# iostm32f205zx register map
Registers are 32-bit, access not given, no defined reset value unless marked. A register's access mark holds for its fields unless they carry their own. Addresses are absolute; registers are grouped by the start of their names; [hi:lo] are bit positions; {n}, {i} and the like mark numbered series.

## DBGMCU
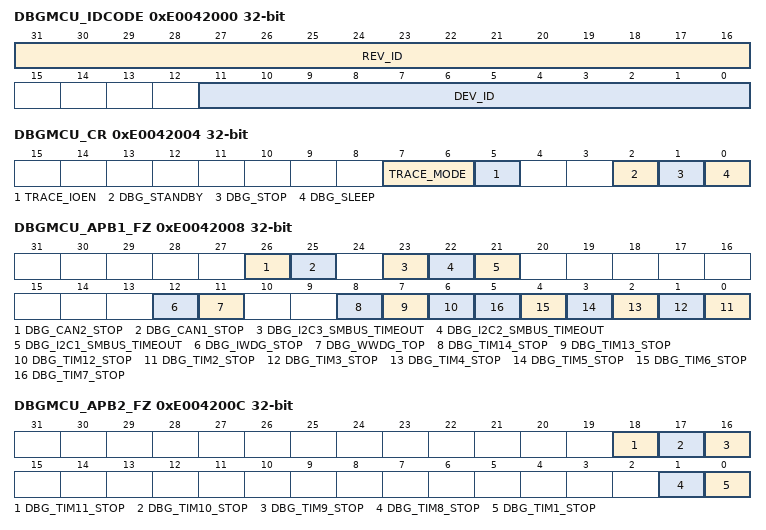
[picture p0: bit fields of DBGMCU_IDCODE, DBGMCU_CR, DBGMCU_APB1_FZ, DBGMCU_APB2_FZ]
0xE0042000 DBGMCU_IDCODE
  [31:16] REV_ID, [11:0] DEV_ID
0xE0042004 DBGMCU_CR
  [7:6] TRACE_MODE, [5] TRACE_IOEN, [2] DBG_STANDBY, [1] DBG_STOP, [0] DBG_SLEEP
0xE0042008 DBGMCU_APB1_FZ
  [26] DBG_CAN2_STOP, [25] DBG_CAN1_STOP, [23] DBG_I2C3_SMBUS_TIMEOUT, [22] DBG_I2C2_SMBUS_TIMEOUT, [21] DBG_I2C1_SMBUS_TIMEOUT, [12] DBG_IWDG_STOP, [11] DBG_WWDG_TOP, [8] DBG_TIM14_STOP, [7] DBG_TIM13_STOP, [6] DBG_TIM12_STOP, [n-2] DBG_TIM{n}_STOP (n=2..7)
0xE004200C DBGMCU_APB2_FZ
  [18] DBG_TIM11_STOP, [17] DBG_TIM10_STOP, [16] DBG_TIM9_STOP, [1] DBG_TIM8_STOP, [0] DBG_TIM1_STOP

## PWR
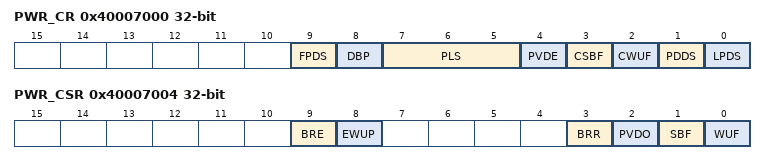
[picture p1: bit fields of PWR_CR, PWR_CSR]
0x40007000 PWR_CR
  [9] FPDS, [8] DBP, [7:5] PLS, [4] PVDE, [3] CSBF, [2] CWUF, [1] PDDS, [0] LPDS
0x40007004 PWR_CSR
  [9] BRE, [8] EWUP, [3] BRR, [2] PVDO, [1] SBF, [0] WUF

## RCC
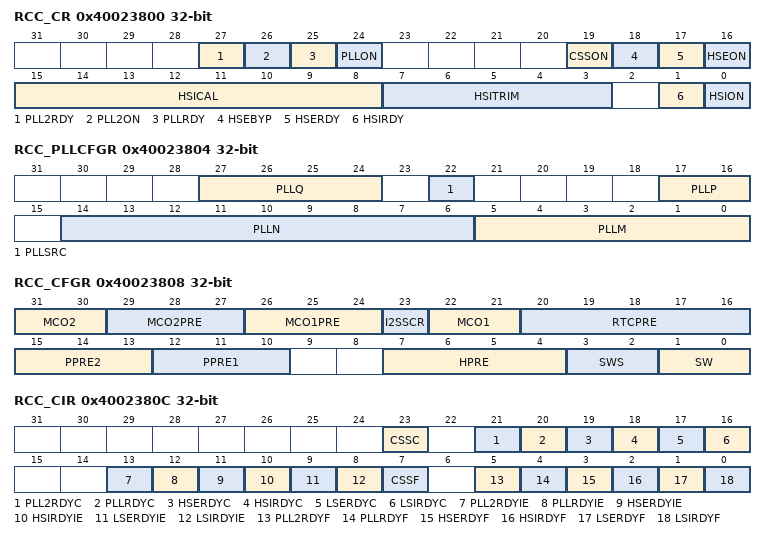
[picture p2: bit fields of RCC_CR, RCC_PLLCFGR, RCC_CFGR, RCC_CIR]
0x40023800 RCC_CR
  [27] PLL2RDY, [26] PLL2ON, [25] PLLRDY, [24] PLLON, [19] CSSON, [18] HSEBYP, [17] HSERDY, [16] HSEON, [15:8] HSICAL, [7:3] HSITRIM, [1] HSIRDY, [0] HSION
0x40023804 RCC_PLLCFGR
  [27:24] PLLQ, [22] PLLSRC, [17:16] PLLP, [14:6] PLLN, [5:0] PLLM
0x40023808 RCC_CFGR
  [31:30] MCO2, [29:27] MCO2PRE, [26:24] MCO1PRE, [23] I2SSCR, [22:21] MCO1, [20:16] RTCPRE, [15:13] PPRE2, [12:10] PPRE1, [7:4] HPRE, [3:2] SWS, [1:0] SW
0x4002380C RCC_CIR
  [23] CSSC, [21] PLL2RDYC, [20] PLLRDYC, [19] HSERDYC, [18] HSIRDYC, [17] LSERDYC, [16] LSIRDYC, [13] PLL2RDYIE, [12] PLLRDYIE, [11] HSERDYIE, [10] HSIRDYIE, [9] LSERDYIE, [8] LSIRDYIE, [7] CSSF, [5] PLL2RDYF, [4] PLLRDYF, [3] HSERDYF, [2] HSIRDYF, [1] LSERDYF, [0] LSIRDYF
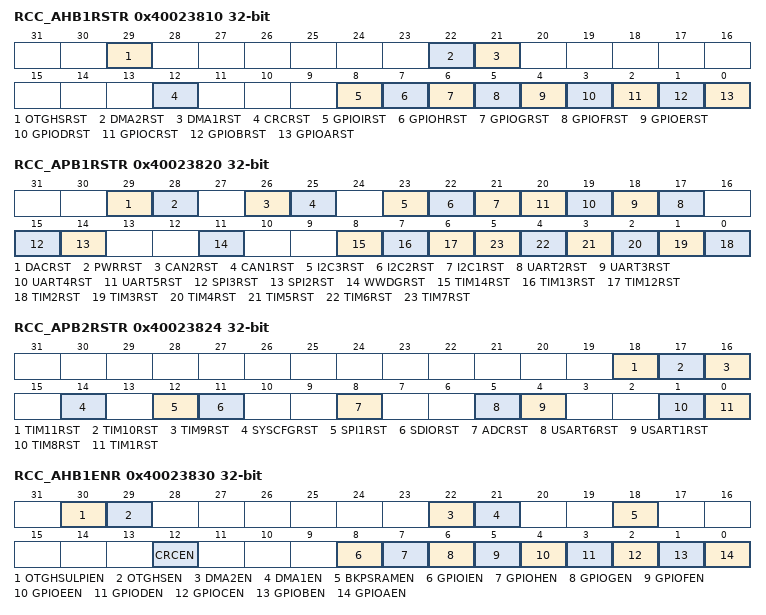
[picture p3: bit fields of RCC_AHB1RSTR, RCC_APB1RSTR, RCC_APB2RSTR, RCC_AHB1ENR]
0x40023810 RCC_AHB1RSTR
  [29] OTGHSRST, [22] DMA2RST, [21] DMA1RST, [12] CRCRST, [8] GPIOIRST, [7] GPIOHRST, [6] GPIOGRST, [5] GPIOFRST, [4] GPIOERST, [3] GPIODRST, [2] GPIOCRST, [1] GPIOBRST, [0] GPIOARST
0x40023814 RCC_AHB2RSTR
  [6] RNGRST
0x40023818 RCC_AHB3RSTR
  [0] FSMCRST
0x40023820 RCC_APB1RSTR
  [29] DACRST, [28] PWRRST, [26] CAN2RST, [25] CAN1RST, [23] I2C3RST, [22] I2C2RST, [21] I2C1RST, [n+15] UART{n}RST (n=2..5), [15] SPI3RST, [14] SPI2RST, [11] WWDGRST, [8] TIM14RST, [7] TIM13RST, [6] TIM12RST, [n-2] TIM{n}RST (n=2..7)
0x40023824 RCC_APB2RSTR
  [18] TIM11RST, [17] TIM10RST, [16] TIM9RST, [14] SYSCFGRST, [12] SPI1RST, [11] SDIORST, [8] ADCRST, [5] USART6RST, [4] USART1RST, [1] TIM8RST, [0] TIM1RST
0x40023830 RCC_AHB1ENR
  [30] OTGHSULPIEN, [29] OTGHSEN, [22] DMA2EN, [21] DMA1EN, [18] BKPSRAMEN, [12] CRCEN, [8] GPIOIEN, [7] GPIOHEN, [6] GPIOGEN, [5] GPIOFEN, [4] GPIOEEN, [3] GPIODEN, [2] GPIOCEN, [1] GPIOBEN, [0] GPIOAEN
0x40023834 RCC_AHB2ENR
  [6] RNGEN
0x40023838 RCC_AHB3ENR
  [0] FSMCEN
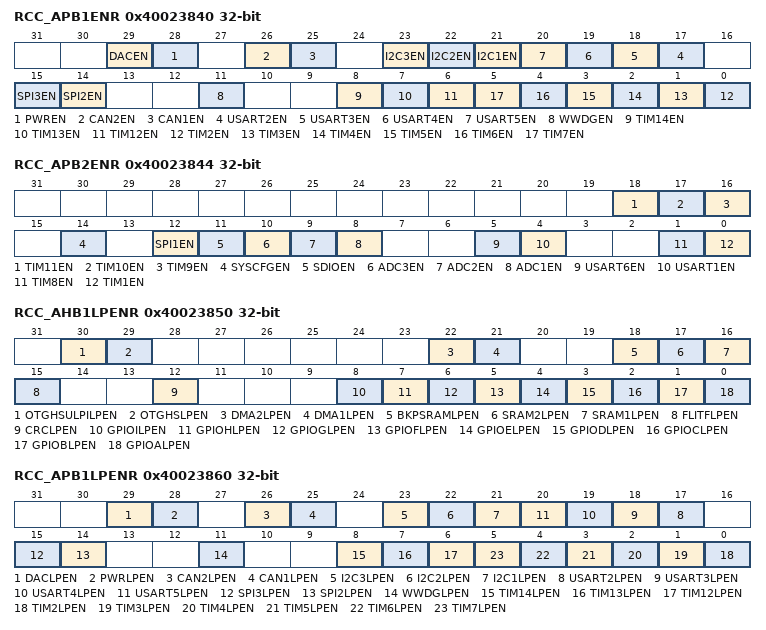
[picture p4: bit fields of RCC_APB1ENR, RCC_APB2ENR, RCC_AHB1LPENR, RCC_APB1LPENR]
0x40023840 RCC_APB1ENR
  [29] DACEN, [28] PWREN, [26] CAN2EN, [25] CAN1EN, [23] I2C3EN, [22] I2C2EN, [21] I2C1EN, [n+15] USART{n}EN (n=2..5), [15] SPI3EN, [14] SPI2EN, [11] WWDGEN, [8] TIM14EN, [7] TIM13EN, [6] TIM12EN, [n-2] TIM{n}EN (n=2..7)
0x40023844 RCC_APB2ENR
  [18] TIM11EN, [17] TIM10EN, [16] TIM9EN, [14] SYSCFGEN, [12] SPI1EN, [11] SDIOEN, [10] ADC3EN, [9] ADC2EN, [8] ADC1EN, [5] USART6EN, [4] USART1EN, [1] TIM8EN, [0] TIM1EN
0x40023850 RCC_AHB1LPENR
  [30] OTGHSULPILPEN, [29] OTGHSLPEN, [22] DMA2LPEN, [21] DMA1LPEN, [18] BKPSRAMLPEN, [17] SRAM2LPEN, [16] SRAM1LPEN, [15] FLITFLPEN, [12] CRCLPEN, [8] GPIOILPEN, [7] GPIOHLPEN, [6] GPIOGLPEN, [5] GPIOFLPEN, [4] GPIOELPEN, [3] GPIODLPEN, [2] GPIOCLPEN, [1] GPIOBLPEN, [0] GPIOALPEN
0x40023854 RCC_AHB2LPENR
  [6] RNGLPEN
0x40023858 RCC_AHB3LPENR
  [0] FSMCLPEN
0x40023860 RCC_APB1LPENR
  [29] DACLPEN, [28] PWRLPEN, [26] CAN2LPEN, [25] CAN1LPEN, [23] I2C3LPEN, [22] I2C2LPEN, [21] I2C1LPEN, [n+15] USART{n}LPEN (n=2..5), [15] SPI3LPEN, [14] SPI2LPEN, [11] WWDGLPEN, [8] TIM14LPEN, [7] TIM13LPEN, [6] TIM12LPEN, [n-2] TIM{n}LPEN (n=2..7)
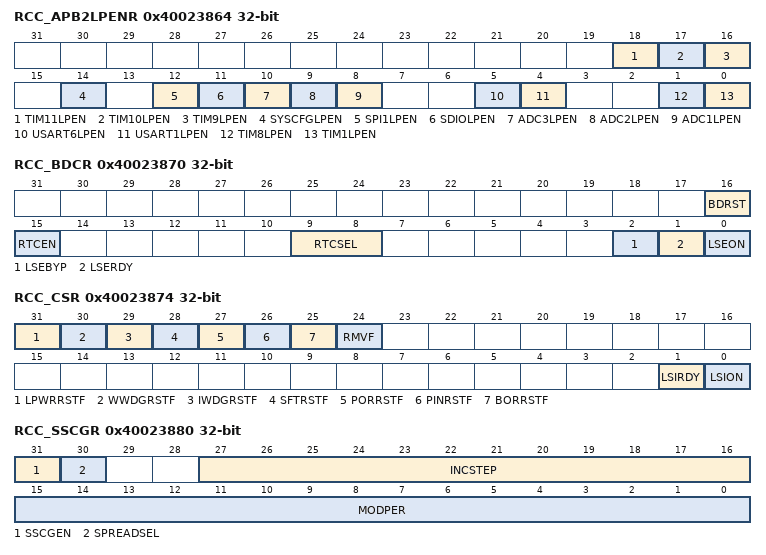
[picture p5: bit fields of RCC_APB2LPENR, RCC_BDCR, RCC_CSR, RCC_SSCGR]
0x40023864 RCC_APB2LPENR
  [18] TIM11LPEN, [17] TIM10LPEN, [16] TIM9LPEN, [14] SYSCFGLPEN, [12] SPI1LPEN, [11] SDIOLPEN, [10] ADC3LPEN, [9] ADC2LPEN, [8] ADC1LPEN, [5] USART6LPEN, [4] USART1LPEN, [1] TIM8LPEN, [0] TIM1LPEN
0x40023870 RCC_BDCR
  [16] BDRST, [15] RTCEN, [9:8] RTCSEL, [2] LSEBYP, [1] LSERDY, [0] LSEON
0x40023874 RCC_CSR
  [31] LPWRRSTF, [30] WWDGRSTF, [29] IWDGRSTF, [28] SFTRSTF, [27] PORRSTF, [26] PINRSTF, [25] BORRSTF, [24] RMVF, [1] LSIRDY, [0] LSION
0x40023880 RCC_SSCGR
  [31] SSCGEN, [30] SPREADSEL, [27:16] INCSTEP, [15:0] MODPER
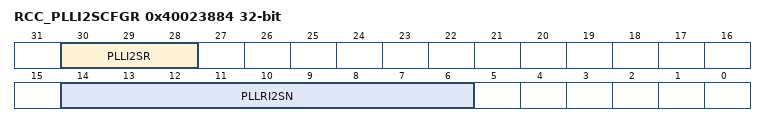
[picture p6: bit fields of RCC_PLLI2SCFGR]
0x40023884 RCC_PLLI2SCFGR
  [30:28] PLLI2SR, [14:6] PLLRI2SN
